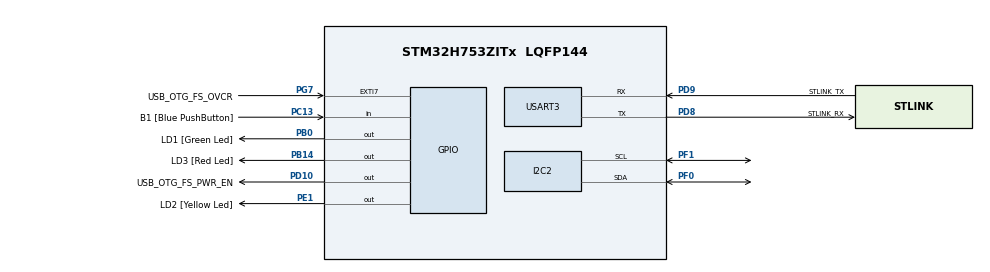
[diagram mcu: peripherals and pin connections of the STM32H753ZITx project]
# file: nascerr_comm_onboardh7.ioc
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CORTEX_M7.CPU_DCache=Disabled
CORTEX_M7.CPU_ICache=Disabled
CORTEX_M7.MPU_Control=__NULL
Dma.Request0=USART3_TX
Dma.USART3_TX.0.Direction=DMA_MEMORY_TO_PERIPH
Dma.USART3_TX.0.EventEnable=DISABLE
Dma.USART3_TX.0.FIFOMode=DMA_FIFOMODE_DISABLE
Dma.USART3_TX.0.Instance=DMA1_Stream0
Dma.USART3_TX.0.MemDataAlignment=DMA_MDATAALIGN_BYTE
Dma.USART3_TX.0.MemInc=DMA_MINC_ENABLE
Dma.USART3_TX.0.Mode=DMA_NORMAL
Dma.USART3_TX.0.PeriphDataAlignment=DMA_PDATAALIGN_BYTE
Dma.USART3_TX.0.PeriphInc=DMA_PINC_DISABLE
Dma.USART3_TX.0.Polarity=HAL_DMAMUX_REQ_GEN_RISING
Dma.USART3_TX.0.Priority=DMA_PRIORITY_LOW
Dma.USART3_TX.0.RequestNumber=1
Dma.USART3_TX.0.SignalID=NONE
Dma.USART3_TX.0.SyncEnable=DISABLE
Dma.USART3_TX.0.SyncPolarity=HAL_DMAMUX_SYNC_NO_EVENT
Dma.USART3_TX.0.SyncRequestNumber=1
Dma.USART3_TX.0.SyncSignalID=NONE
I2C2.OwnAddress=0x12
I2C2.Timing=0x107075B0
Mcu.Family=STM32H7
Mcu.Name=STM32H753ZITx
Mcu.Package=LQFP144
NVIC.DMA1_Stream0_IRQn=true\:0\:0\:false\:false\:true\:false\:true\:true
NVIC.I2C2_ER_IRQn=true\:0\:0\:false\:false\:true\:true\:true\:true
NVIC.I2C2_EV_IRQn=true\:0\:0\:false\:false\:true\:true\:true\:true
NVIC.PriorityGroup=NVIC_PRIORITYGROUP_4
NVIC.USART3_IRQn=true\:0\:0\:false\:false\:true\:true\:true\:true
PA1.Signal=ETH_REF_CLK
PA11.Signal=USB_OTG_FS_DM
PA12.Signal=USB_OTG_FS_DP
PA2.Signal=ETH_MDIO
PA7.Signal=ETH_CRS_DV
PA8.Signal=USB_OTG_FS_SOF
PA9.Signal=USB_OTG_FS_VBUS
PB0.GPIO_Label=LD1 [Green Led]
PB0.Signal=GPIO_Output
PB13.Signal=ETH_TXD1
PB14.GPIO_Label=LD3 [Red Led]
PB14.Signal=GPIO_Output
PC1.Signal=ETH_MDC
PC13.GPIO_Label=B1 [Blue PushButton]
PC13.Signal=GPIO_Input
PC14-OSC32_IN\ (OSC32_IN).Mode=LSE-External-Oscillator
PC14-OSC32_IN\ (OSC32_IN).Signal=RCC_OSC32_IN
PC15-OSC32_OUT\ (OSC32_OUT).Mode=LSE-External-Oscillator
PC15-OSC32_OUT\ (OSC32_OUT).Signal=RCC_OSC32_OUT
PC4.Signal=ETH_RXD0
PC5.Signal=ETH_RXD1
PD10.GPIO_Label=USB_OTG_FS_PWR_EN
PD10.Signal=GPIO_Output
PD8.GPIO_Label=STLINK_RX
PD8.Mode=Asynchronous
PD8.Signal=USART3_TX
PD9.GPIO_Label=STLINK_TX
PD9.Mode=Asynchronous
PD9.Signal=USART3_RX
PE1.GPIO_Label=LD2 [Yellow Led]
PE1.Signal=GPIO_Output
PF0.GPIO_Pu=GPIO_NOPULL
PF0.GPIO_Speed=GPIO_SPEED_FREQ_VERY_HIGH
PF0.Mode=I2C
PF0.Signal=I2C2_SDA
PF1.GPIO_Pu=GPIO_NOPULL
PF1.GPIO_Speed=GPIO_SPEED_FREQ_VERY_HIGH
PF1.Mode=I2C
PF1.Signal=I2C2_SCL
PG11.Signal=ETH_TX_EN
PG13.Signal=ETH_TXD0
PG7.GPIO_Label=USB_OTG_FS_OVCR
PG7.Signal=GPXTI7
PH0-OSC_IN\ (PH0).Mode=HSE-External-Oscillator
PH0-OSC_IN\ (PH0).Signal=RCC_OSC_IN
PH1-OSC_OUT\ (PH1).Mode=HSE-External-Oscillator
PH1-OSC_OUT\ (PH1).Signal=RCC_OSC_OUT
ProjectManager.HeapSize=0x200
ProjectManager.StackSize=0x400
ProjectManager.TargetToolchain=STM32CubeIDE
RCC.ADCFreq_Value=129000000
RCC.APB1Freq_Value=60000000
RCC.APB2Freq_Value=60000000
RCC.APB3Freq_Value=60000000
RCC.APB4Freq_Value=60000000
RCC.CortexFreq_Value=120000000
RCC.D1PPRE=RCC_APB3_DIV2
RCC.D2PPRE1=RCC_APB1_DIV2
RCC.D2PPRE2=RCC_APB2_DIV2
RCC.D3PPRE=RCC_APB4_DIV2
RCC.DIVM1=4
RCC.DIVN1=15
RCC.DIVQ1=4
RCC.HCLKFreq_Value=120000000
RCC.HSE_VALUE=8000000
RCC.PLL2FRACN=0
RCC.PLL3FRACN=0
RCC.PLLFRACN=0
RCC.PWR_Regulator_Voltage_Scale=PWR_REGULATOR_VOLTAGE_SCALE2
RCC.SYSCLKFreq_VALUE=120000000
RCC.SYSCLKSource=RCC_SYSCLKSOURCE_PLLCLK
RCC.USBFreq_Value=60000000
USART3.VirtualMode-Asynchronous=VM_ASYNC
board=NUCLEO-H753ZI

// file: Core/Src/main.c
/* USER CODE BEGIN Header */
/**
  ******************************************************************************
  * @file           : main.c
  * @brief          : Main program body
  ******************************************************************************
  * @attention
  *
  * Copyright (c) 2024 STMicroelectronics.
  * All rights reserved.
  *
  * This software is licensed under terms that can be found in the LICENSE file
  * in the root directory of this software component.
  * If no LICENSE file comes with this software, it is provided AS-IS.
  *
  ******************************************************************************
  */
/* USER CODE END Header */
#include "main.h"
#include "dma.h"
#include "i2c.h"
#include "usart.h"
#include "gpio.h"

/* USER CODE BEGIN Includes */
#include <stdio.h>
/* USER CODE END Includes */

/* USER CODE BEGIN PD */
#define RxSIZE  1
/* USER CODE END PD */

/* USER CODE BEGIN PM */
uint8_t rx_buffer[RxSIZE];
uint8_t numarray[3];
/* USER CODE END PM */

void SystemClock_Config(void);

/* USER CODE BEGIN 0 */
int _write(int file, char *ptr, int len)
{
	HAL_UART_Transmit_DMA(&huart3, (uint8_t*) ptr, len);

	return len;
}
/* USER CODE END 0 */

int main(void)
{

  /* MCU Configuration--------------------------------------------------------*/

  /* Reset of all peripherals, Initializes the Flash interface and the Systick. */
  HAL_Init();

  /* Configure the system clock */
  SystemClock_Config();

  /* Initialize all configured peripherals */
  MX_GPIO_Init();
  MX_DMA_Init();
  MX_USART3_UART_Init();
  MX_I2C2_Init();
  /* USER CODE BEGIN 2 */
  if (HAL_I2C_EnableListen_IT(&hi2c2) != HAL_OK)
  {
	  Error_Handler();
  }
  printf("Application Initialized...\r\n");
  /* USER CODE END 2 */

  /* Infinite loop */
  /* USER CODE BEGIN WHILE */
  while (1)
  {
//	  HAL_I2C_Slave_Receive(&hi2c2, (uint8_t *) rx_buffer, RxSIZE, HAL_MAX_DELAY);
//	  HAL_GPIO_TogglePin(LD1_GPIO_Port, LD1_Pin);
//	  printf("Recebeu um dado: %c \r\n", (char) rx_buffer[0]);
//	  HAL_Delay(500);

    /* USER CODE END WHILE */

  }
}

void SystemClock_Config(void)
{
  RCC_OscInitTypeDef RCC_OscInitStruct = {0};
  RCC_ClkInitTypeDef RCC_ClkInitStruct = {0};

  /** Supply configuration update enable
  */
  HAL_PWREx_ConfigSupply(PWR_LDO_SUPPLY);

  /** Configure the main internal regulator output voltage
  */
  __HAL_PWR_VOLTAGESCALING_CONFIG(PWR_REGULATOR_VOLTAGE_SCALE2);

  while(!__HAL_PWR_GET_FLAG(PWR_FLAG_VOSRDY)) {}

  /** Initializes the RCC Oscillators according to the specified parameters
  * in the RCC_OscInitTypeDef structure.
  */
  RCC_OscInitStruct.OscillatorType = RCC_OSCILLATORTYPE_HSI;
  RCC_OscInitStruct.HSIState = RCC_HSI_DIV1;
  RCC_OscInitStruct.HSICalibrationValue = RCC_HSICALIBRATION_DEFAULT;
  RCC_OscInitStruct.PLL.PLLState = RCC_PLL_ON;
  RCC_OscInitStruct.PLL.PLLSource = RCC_PLLSOURCE_HSI;
  RCC_OscInitStruct.PLL.PLLM = 4;
  RCC_OscInitStruct.PLL.PLLN = 15;
  RCC_OscInitStruct.PLL.PLLP = 2;
  RCC_OscInitStruct.PLL.PLLQ = 4;
  RCC_OscInitStruct.PLL.PLLR = 2;
  RCC_OscInitStruct.PLL.PLLRGE = RCC_PLL1VCIRANGE_3;
  RCC_OscInitStruct.PLL.PLLVCOSEL = RCC_PLL1VCOWIDE;
  RCC_OscInitStruct.PLL.PLLFRACN = 0;
  if (HAL_RCC_OscConfig(&RCC_OscInitStruct) != HAL_OK)
  {
    Error_Handler();
  }

  /** Initializes the CPU, AHB and APB buses clocks
  */
  RCC_ClkInitStruct.ClockType = RCC_CLOCKTYPE_HCLK|RCC_CLOCKTYPE_SYSCLK
                              |RCC_CLOCKTYPE_PCLK1|RCC_CLOCKTYPE_PCLK2
                              |RCC_CLOCKTYPE_D3PCLK1|RCC_CLOCKTYPE_D1PCLK1;
  RCC_ClkInitStruct.SYSCLKSource = RCC_SYSCLKSOURCE_PLLCLK;
  RCC_ClkInitStruct.SYSCLKDivider = RCC_SYSCLK_DIV1;
  RCC_ClkInitStruct.AHBCLKDivider = RCC_HCLK_DIV1;
  RCC_ClkInitStruct.APB3CLKDivider = RCC_APB3_DIV2;
  RCC_ClkInitStruct.APB1CLKDivider = RCC_APB1_DIV2;
  RCC_ClkInitStruct.APB2CLKDivider = RCC_APB2_DIV2;
  RCC_ClkInitStruct.APB4CLKDivider = RCC_APB4_DIV2;

  if (HAL_RCC_ClockConfig(&RCC_ClkInitStruct, FLASH_LATENCY_2) != HAL_OK)
  {
    Error_Handler();
  }
}

void Error_Handler(void)
{
  __disable_irq();
  while (1)
  {
  }
}
